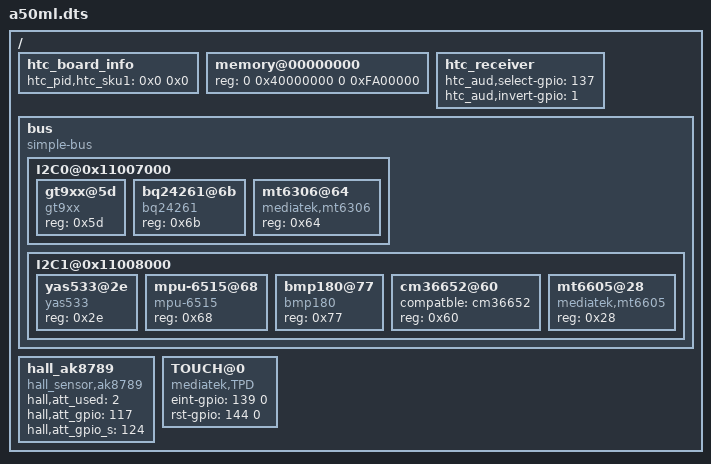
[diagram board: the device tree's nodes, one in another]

/dts-v1/;

/include/ "mt6752.dtsi"
/include/ "htc_features.dtsi"
/include/ "mt6752-touch-a50.dtsi"

/ {
	htc_board_info {
		htc_pid,htc_sku1 = <0x0 0x0>;
	};

	memory@00000000 {
		device_type = "memory";
		reg = <0 0x40000000 0 0xFA00000>;
	};

	htc_receiver{
		htc_aud,select-gpio = <137>;
		htc_aud,invert-gpio = <1>;
	};

	bus {
		compatible = "simple-bus";
		#address-cells = <1>;
		#size-cells = <1>;
		ranges = <0 0 0 0xffffffff>;

		I2C0@0x11007000 {
			gt9xx@5d {
				compatible = "gt9xx";
				reg = <0x5d>;
			};

			bq24261@6b {
				compatible = "bq24261";
				reg = <0x6b>;
			};

			mt6306@64 {
				compatible = "mediatek,mt6306";
				reg = <0x64>;
			};
		};

		I2C1@0x11008000 {
			yas533@2e {
				compatible = "yas533";
				reg = <0x2e>;
			};

			mpu-6515@68 {
				compatible = "mpu-6515";
				reg = <0x68>;
			};

			bmp180@77 {
				compatible = "bmp180";
				reg = <0x77>;
			};

			cm36652@60 {
				compatble = "cm36652";
				reg = <0x60>;
			};

			mt6605@28 {
				compatible = "mediatek,mt6605";
				reg = <0x28>;
			};

		};

	};

	hall_ak8789 {
		compatible = "hall_sensor,ak8789";
		hall,att_used = <2>;
		hall,att_gpio = <117>;
		hall,att_gpio_s = <124>;
	};


    TOUCH@0 {
	    compatible = "mediatek,TPD";
        eint-gpio = <139 0>;
        rst-gpio = <144 0>;
    };
};
